# STM32L452xx register map
File version: 1.0
Registers are 32-bit, read-write, reset 0x0 unless marked. A register's access mark holds for its fields unless they carry their own. Offsets are from the block's base; [hi:lo] are bit positions; {n}, {i} and the like mark numbered series.

## USB — Universal Serial Bus Full Speed Device
Base 0x40006800
{0x0+4i} EP{i}R 16-bit (i=0..7) — USB Endpoint {i} register
0x40 CNTR 16-bit — Control register
0x44 ISTR 16-bit — Interrupt status register
0x48 FNR 16-bit — Frame number register
0x4C DADDR 16-bit — Device address register
0x50 BTABLE 16-bit — Buffer Table address register
0x54 LPMCSR 16-bit — LPM Control and Status register
0x58 BCDR 16-bit — Battery Charging detector register

## PWR — Power Control
Base 0x40007000
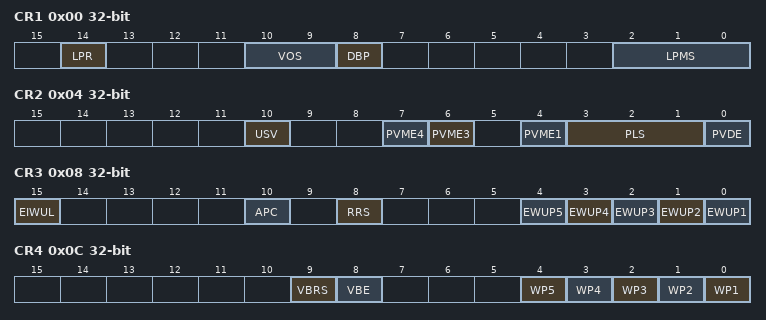
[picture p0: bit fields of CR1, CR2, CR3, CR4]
0x00 CR1 — PWR power control register 1
  [14] LPR — Regulator low-power mode
  [10:9] VOS — VOS[1:0] bits (Regulator voltage scaling output selection)
    1=SCALE1; 2=SCALE2
  [8] DBP — Disable Back-up domain Protection
  [2:0] LPMS — Low-power mode selection field
    0=STOP0; 1=STOP1; 2=STOP2; 3=STANDBY; 4=SHUTDOWN
0x04 CR2 — PWR power control register 2
  [10] USV — VDD USB Supply Valid
  [7] PVME4 — PVM 4 Enable
  [6] PVME3 — PVM 3 Enable
  [4] PVME1 — PVM 1 Enable
  [3:1] PLS — PVD level selection
    {v}=PVDLEVEL_{v} (v=0..7)
  [0] PVDE — Power Voltage Detector Enable
0x08 CR3 — PWR power control register 3
  [15] EIWUL — Enable Internal Wake-up line
  [10] APC — Apply pull-up and pull-down configuration
  [8] RRS — SRAM2 Retention in Stand-by mode
    0=NO_SRAM2_RETENTION; 1=FULL_SRAM2_RETENTION
  [n-1] EWUP{n} (n=1..5) — Enable Wake-Up Pin {n}
0x0C CR4 — PWR power control register 4
  [9] VBRS — VBAT Battery charging Resistor Selection
    0=CHARG_RESISTOR_5K; 1=CHARGRESISTOR_1_5K
  [8] VBE — VBAT Battery charging Enable
  [n-1] WP{n} (n=1..5) — Wake-Up Pin {n} polarity
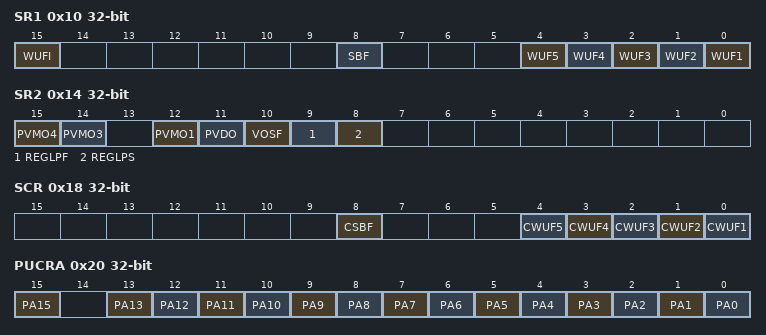
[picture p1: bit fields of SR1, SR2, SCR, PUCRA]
0x10 SR1 — PWR power status register 1
  [15] WUFI — Wake-Up Flag Internal
  [8] SBF — Stand-By Flag
  [n-1] WUF{n} (n=1..5) — Wake-up Flag {n}
0x14 SR2 — PWR power status register 2
  [15] PVMO4 — Peripheral Voltage Monitoring Output 4
  [14] PVMO3 — Peripheral Voltage Monitoring Output 3
  [12] PVMO1 — Peripheral Voltage Monitoring Output 1
  [11] PVDO — Power Voltage Detector Output
  [10] VOSF — Voltage Scaling Flag
  [9] REGLPF — Low-power Regulator Flag
  [8] REGLPS — Low-power Regulator Started
0x18 SCR — PWR power status reset register
  [8] CSBF — Clear Stand-By Flag
  [n-1] CWUF{n} (n=1..5) — Clear Wake-up Flag {n}
0x20 PUCRA — Pull_up control register of portA
  [15] PA15 — Port PA15 Pull-Up set
  [n] PA{n} (n=0..13) — Port PA{n} Pull-Up set
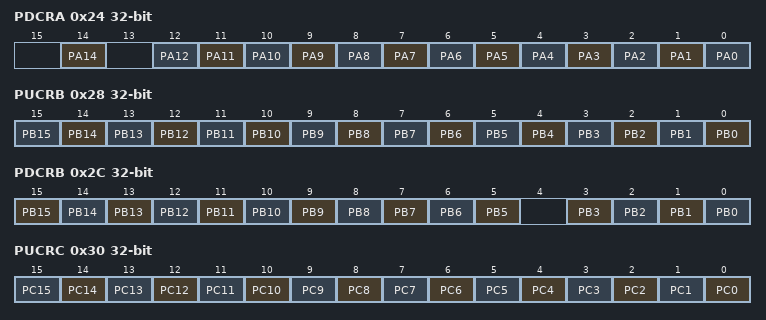
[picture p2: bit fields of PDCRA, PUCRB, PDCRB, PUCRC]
0x24 PDCRA — Pull_Down control register of portA
  [14] PA14 — Port PA14 Pull-Down set
  [n] PA{n} (n=0..12) — Port PA{n} Pull-Down set
0x28 PUCRB — Pull_up control register of portB
  [n] PB{n} (n=0..15) — Port PB{n} Pull-Up set
0x2C PDCRB — Pull_Down control register of portB
  [n] PB{n} (n=5..15) — Port PB{n} Pull-Down set
  [n] PB{n} (n=0..3) — Port PB{n} Pull-Down set
0x30 PUCRC — Pull_up control register of portC
  [n] PC{n} (n=0..15) — Port PC{n} Pull-Up set
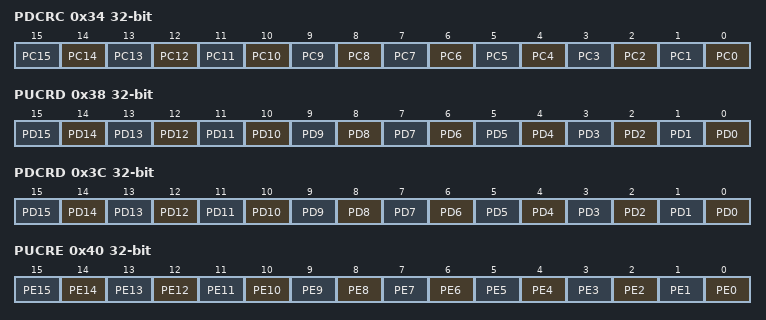
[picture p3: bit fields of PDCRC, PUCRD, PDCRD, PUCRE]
0x34 PDCRC — Pull_Down control register of portC
  [n] PC{n} (n=0..15) — Port PC{n} Pull-Down set
0x38 PUCRD — Pull_up control register of portD
  [n] PD{n} (n=0..15) — Port PD{n} Pull-Up set
0x3C PDCRD — Pull_Down control register of portD
  [n] PD{n} (n=0..15) — Port PD{n} Pull-Down set
0x40 PUCRE — Pull_up control register of portE
  [n] PE{n} (n=0..15) — Port PE{n} Pull-Up set
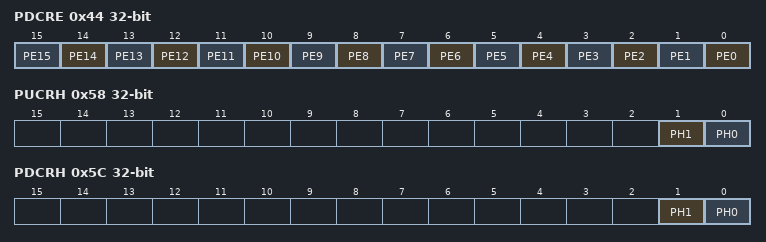
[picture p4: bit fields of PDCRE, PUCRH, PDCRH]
0x44 PDCRE — Pull_Down control register of portE
  [n] PE{n} (n=0..15) — Port PE{n} Pull-Down set
0x58 PUCRH — Pull_up control register of portH
  [1] PH1 — Port PH1 Pull-Up set
  [0] PH0 — Port PH0 Pull-Up set
0x5C PDCRH — Pull_Down control register of portH
  [1] PH1 — Port PH1 Pull-Down set
  [0] PH0 — Port PH0 Pull-Down set

## DAC — Digital to Analog Converter
Base 0x40007400
Same registers: DAC1 0x40007400 (alternate view of DAC)
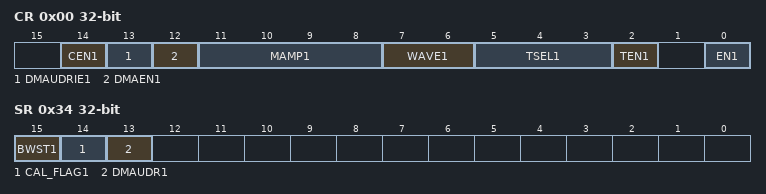
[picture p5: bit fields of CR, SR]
0x00 CR — DAC control register
  [14] CEN1 — DAC channel 1 calibration enable >
  [13] DMAUDRIE1 — DAC channel 1 DMA underrun interrupt enable >
  [12] DMAEN1 — DAC channel1 DMA enable
  [11:8] MAMP1 — MAMP1[3:0] (DAC channel1 Mask/Amplitude selector)
  [7:6] WAVE1 — WAVE1[1:0] (DAC channel1 noise/triangle wave generation enable)
  [5:3] TSEL1 — TSEL1[2:0] (DAC channel1 Trigger selection)
  [2] TEN1 — DAC channel1 Trigger enable
  [0] EN1 — DAC channel1 enable
0x04 SWTRIGR — DAC software trigger register
  [0] SWTRIG1 — DAC channel1 software trigger
0x08 DHR12R1 — DAC channel1 12-bit right-aligned data holding register
  [11:0] DACC1DHR — DAC channel1 12-bit Right aligned data
0x0C DHR12L1 — DAC channel1 12-bit left aligned data holding register
  [15:4] DACC1DHR — DAC channel1 12-bit Left aligned data
0x10 DHR8R1 — DAC channel1 8-bit right aligned data holding register
  [7:0] DACC1DHR — DAC channel1 8-bit Right aligned data
0x14 DHR12R2 — DAC channel2 12-bit right aligned data holding register
0x18 DHR12L2 — DAC channel2 12-bit left aligned data holding register
0x1C DHR8R2 — DAC channel2 8-bit right-aligned data holding register
0x20 DHR12RD — Dual DAC 12-bit right-aligned data holding register
  [11:0] DACC1DHR — DAC channel1 12-bit Right aligned data
0x24 DHR12LD — DUAL DAC 12-bit left aligned data holding register
  [15:4] DACC1DHR — DAC channel1 12-bit Left aligned data
0x28 DHR8RD — DUAL DAC 8-bit right aligned data holding register
  [7:0] DACC1DHR — DAC channel1 8-bit Right aligned data
0x2C DOR1 — DAC channel1 data output register
  [11:0] DACC1DOR — DAC channel1 data output
0x30 DOR2 — DAC channel2 data output register
0x34 SR — DAC status register
  [15] BWST1 — DAC channel1 busy writing sample time flag
  [14] CAL_FLAG1 — DAC channel1 calibration offset status
  [13] DMAUDR1 — DAC channel1 DMA underrun flag
0x38 CCR — DAC calibration control register
  [4:0] OTRIM1 — DAC channel1 offset trimming value
0x3C MCR — DAC mode control register
  [2:0] MODE1 — MODE1[2:0] (DAC channel1 mode)
0x40 SHSR1 — DAC Sample and Hold sample time register 1
  [9:0] TSAMPLE1 — DAC channel1 sample time
0x44 SHSR2 — DAC Sample and Hold sample time register 2
0x48 SHHR — DAC Sample and Hold hold time register
  [9:0] THOLD1 — DAC channel1 hold time
0x4C SHRR — DAC Sample and Hold refresh time register
  [7:0] TREFRESH1 — DAC channel1 refresh time
